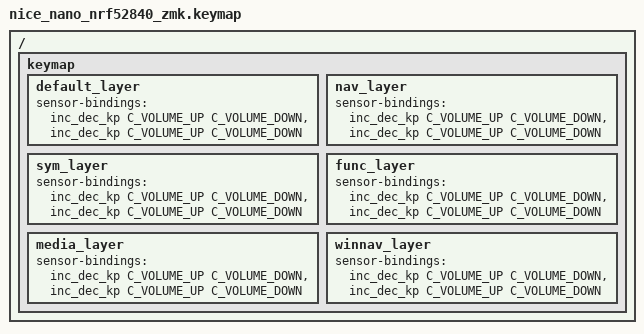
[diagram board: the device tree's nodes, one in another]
/ {
    keymap {
        default_layer {
            sensor-bindings = <&inc_dec_kp C_VOLUME_UP C_VOLUME_DOWN &inc_dec_kp C_VOLUME_UP C_VOLUME_DOWN>;
        };
        nav_layer {
            sensor-bindings = <&inc_dec_kp C_VOLUME_UP C_VOLUME_DOWN &inc_dec_kp C_VOLUME_UP C_VOLUME_DOWN>;
        };
        sym_layer {
            sensor-bindings = <&inc_dec_kp C_VOLUME_UP C_VOLUME_DOWN &inc_dec_kp C_VOLUME_UP C_VOLUME_DOWN>;
        };
        func_layer {
            sensor-bindings = <&inc_dec_kp C_VOLUME_UP C_VOLUME_DOWN &inc_dec_kp C_VOLUME_UP C_VOLUME_DOWN>;
        };
        media_layer {
            sensor-bindings = <&inc_dec_kp C_VOLUME_UP C_VOLUME_DOWN &inc_dec_kp C_VOLUME_UP C_VOLUME_DOWN>;
        };
        winnav_layer {
            sensor-bindings = <&inc_dec_kp C_VOLUME_UP C_VOLUME_DOWN &inc_dec_kp C_VOLUME_UP C_VOLUME_DOWN>;
        };
    }
}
